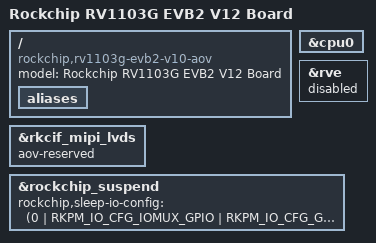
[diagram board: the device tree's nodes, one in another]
// SPDX-License-Identifier: (GPL-2.0+ OR MIT)
/*
 * Copyright (c) 2023 Rockchip Electronics Co., Ltd.
 */

/dts-v1/;

#include "rv1103g-evb2-v10.dts"

/ {
	model = "Rockchip RV1103G EVB2 V12 Board";
	compatible = "rockchip,rv1103g-evb2-v10-aov", "rockchip,rv1103";

	aliases {
		/delete-property/ csi2dphy1;
		/delete-property/ csi2dphy2;
		/delete-property/ ethernet0;
		/delete-property/ i2c0;
		/delete-property/ i2c1;
		/delete-property/ i2c2;
		/delete-property/ i2c3;
		/delete-property/ mmc0;
		/delete-property/ mmc1;
		/delete-property/ rkcif_mipi_lvds1;
		/delete-property/ serial0;
		/delete-property/ serial1;
		/delete-property/ serial3;
		/delete-property/ serial4;
		/delete-property/ serial5;
		/delete-property/ spi0;
		/delete-property/ spi1;
	};
};

&cpu0 {
	/delete-property/ clocks;
	/delete-property/ operating-points-v2;
};

/delete-node/ &emmc;
/delete-node/ &gmac;
/delete-node/ &i2c0;
/delete-node/ &i2c1;
/delete-node/ &i2c2;
/delete-node/ &i2c3;
/delete-node/ &rkcif_dvp;
/delete-node/ &rkcif_dvp_sditf;
/delete-node/ &rkcif_mipi_lvds1;
/delete-node/ &rkcif_mipi_lvds1_sditf;
/delete-node/ &spi0;
/delete-node/ &spi1;
/delete-node/ &uart0;
/delete-node/ &uart1;
/delete-node/ &uart3;
/delete-node/ &uart4;
/delete-node/ &uart5;

&rkcif_mipi_lvds {
	status = "okay";
	aov-reserved;
};

&rve {
	status = "disabled";
};

&rockchip_suspend {
	status = "okay";
	rockchip,sleep-io-config = <
		(0
		| RKPM_IO_CFG_IOMUX_GPIO
		| RKPM_IO_CFG_GPIO_DIR_INPUT
		| RKPM_IO_CFG_PULL_DOWN
		| RKPM_IO_CFG_ID(0)
		)
		(0
		| RKPM_IO_CFG_IOMUX_GPIO
		| RKPM_IO_CFG_GPIO_DIR_INPUT
		| RKPM_IO_CFG_PULL_DOWN
		| RKPM_IO_CFG_ID(1)
		)
		(0
		| RKPM_IO_CFG_IOMUX_GPIO
		| RKPM_IO_CFG_GPIO_DIR_INPUT
		| RKPM_IO_CFG_PULL_DOWN
		| RKPM_IO_CFG_ID(2)
		)
		(0
		| RKPM_IO_CFG_IOMUX_GPIO
		| RKPM_IO_CFG_GPIO_DIR_INPUT
		| RKPM_IO_CFG_PULL_DOWN
		| RKPM_IO_CFG_ID(3)
		)
		(0
		| RKPM_IO_CFG_IOMUX_GPIO
		| RKPM_IO_CFG_GPIO_DIR_INPUT
		| RKPM_IO_CFG_PULL_UP
		| RKPM_IO_CFG_ID(4)
		)
		(0
		| RKPM_IO_CFG_IOMUX_GPIO
		| RKPM_IO_CFG_GPIO_DIR_INPUT
		| RKPM_IO_CFG_PULL_DOWN
		| RKPM_IO_CFG_ID(5)
		)
		(0
		| RKPM_IO_CFG_IOMUX_GPIO
		| RKPM_IO_CFG_GPIO_DIR_INPUT
		| RKPM_IO_CFG_PULL_DOWN
		| RKPM_IO_CFG_ID(6)
		)
	>;
};
